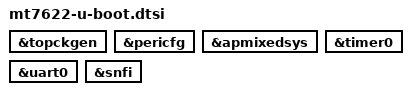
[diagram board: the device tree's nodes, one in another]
// SPDX-License-Identifier: GPL-2.0
/*
 * Copyright (c) 2019 MediaTek Inc.
 * Author: Sam Shih <sam.shih@mediatek.com>
 */

&topckgen {
	u-boot,dm-all;
};

&pericfg {
	u-boot,dm-all;
};

&apmixedsys {
	u-boot,dm-all;
};

&timer0 {
	u-boot,dm-all;
};

&uart0 {
	u-boot,dm-all;
};

&snfi {
	u-boot,dm-all;
};
